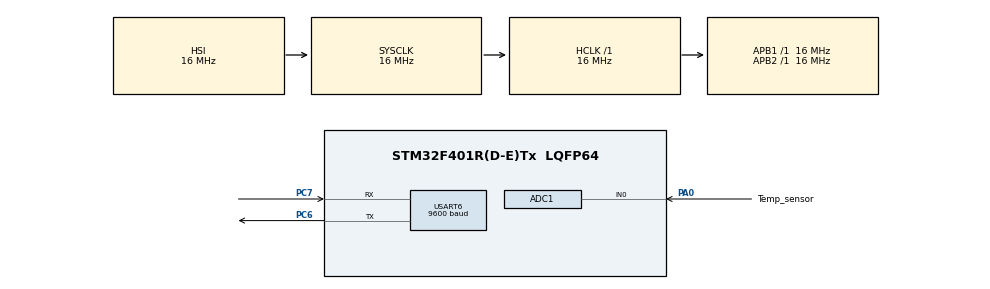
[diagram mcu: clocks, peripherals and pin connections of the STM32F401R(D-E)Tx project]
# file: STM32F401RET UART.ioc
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ADC1.Channel-2\#ChannelRegularConversion=ADC_CHANNEL_0
ADC1.NbrOfConversionFlag=1
ADC1.Rank-2\#ChannelRegularConversion=1
ADC1.Resolution=ADC_RESOLUTION_10B
ADC1.SamplingTime-2\#ChannelRegularConversion=ADC_SAMPLETIME_3CYCLES
ADC1.master=1
Mcu.Family=STM32F4
Mcu.Name=STM32F401R(D-E)Tx
Mcu.Package=LQFP64
NVIC.PriorityGroup=NVIC_PRIORITYGROUP_4
PA0-WKUP.GPIO_Label=Temp_sensor
PA0-WKUP.Signal=ADCx_IN0
PC6.Mode=Asynchronous
PC6.Signal=USART6_TX
PC7.Mode=Asynchronous
PC7.Signal=USART6_RX
ProjectManager.HeapSize=0x200
ProjectManager.StackSize=0x400
ProjectManager.TargetToolchain=MDK-ARM V5.27
RCC.AHBFreq_Value=16000000
RCC.APB1Freq_Value=16000000
RCC.APB2Freq_Value=16000000
RCC.CortexFreq_Value=16000000
RCC.HSE_VALUE=25000000
RCC.HSI_VALUE=16000000
RCC.LSE_VALUE=32768
RCC.SYSCLKFreq_VALUE=16000000
RCC.VCOOutputFreq_Value=192000000
SH.ADCx_IN0.0=ADC1_IN0,IN0
USART6.BaudRate=9600
USART6.VirtualMode=VM_ASYNC
board=custom

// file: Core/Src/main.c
/* USER CODE BEGIN Header */
/**
  ******************************************************************************
  * @file           : main.c
  * @brief          : Main program body
  ******************************************************************************
/*Info
*Developer: Harry Hoa Huynh
*Email: harry.hoa.huynh.01@gmail.com
*Date: 4/11/2021
*Version: 001
*Main goal: 	1. Collect temperature data using STM32F401RE
*							2. Send data to STM32F429ZI via UART using Polling
*							3. Display data on the LCD on the STM32F429ZI
*
*STM32F401RE Set up:
*1. Temperature MCP9700A: PA0	[ADC 10bits with 13 clock cycles]
*2. UART: TX = PC6 | RX = PC7 [Baud rate of 9600bs, Word length of 8b]
*
*STM32F429ZI Set up
*1. UART: TX = PC6 | RX = PC7 [Baud rate of 9600bs, Word length of 8b]
*2. Display the temperature via LCD
*		*	RS	PD1
*			EN	PD7
*			DB4	PD6
*			DB5	PD5
*			DB6	PD4
*			DB7	PD3
*
*		Component:
*		1. STM Nucleo STM32F429ZI
*		2. STM Nucleo STM32F401RE
*		3. Temperature MCP9700A
*		4. LCD HC16102

*/
/* USER CODE END Header */
#include "main.h"

/* USER CODE BEGIN Includes */
#include <string.h>

/* USER CODE END Includes */

ADC_HandleTypeDef hadc1;
UART_HandleTypeDef huart6;

/* USER CODE BEGIN PV */
uint32_t ADC_value;
float temperature_value;
char TX_buffer[4]={0};
char RX_buffer[4]={0};
/* USER CODE END PV */

void SystemClock_Config(void);
static void MX_GPIO_Init(void);
static void MX_USART6_UART_Init(void);
static void MX_ADC1_Init(void);

int main(void)
{

  /* MCU Configuration--------------------------------------------------------*/

  /* Reset of all peripherals, Initializes the Flash interface and the Systick. */
  HAL_Init();

  /* Configure the system clock */
  SystemClock_Config();

  /* Initialize all configured peripherals */
  MX_GPIO_Init();
  MX_USART6_UART_Init();
  MX_ADC1_Init();

  /* Infinite loop */
  while (1)
  {

    /* USER CODE BEGIN 3 */

		//Collect Temperature Data
		HAL_ADC_Start(&hadc1);
		HAL_ADC_PollForConversion(&hadc1, HAL_MAX_DELAY);
		ADC_value = HAL_ADC_GetValue(&hadc1);
		temperature_value = ((ADC_value*3.3)/1024 -0.5)/0.01;		//Input of 3.3V to the Sensor | Sensor Output Calibrated with  0.5V offset (MCP9700/9700A datasheet)

		//Transfer Data via UART
		sprintf(TX_buffer, "%d", ADC_value);	//Return a formatted string
		HAL_UART_Transmit(&huart6, (uint8_t*)TX_buffer, 5, 100);
		HAL_Delay(100);
  }
  /* USER CODE END 3 */
}

void SystemClock_Config(void)
{
  RCC_OscInitTypeDef RCC_OscInitStruct = {0};
  RCC_ClkInitTypeDef RCC_ClkInitStruct = {0};

  /** Configure the main internal regulator output voltage
  */
  __HAL_RCC_PWR_CLK_ENABLE();
  __HAL_PWR_VOLTAGESCALING_CONFIG(PWR_REGULATOR_VOLTAGE_SCALE2);
  /** Initializes the RCC Oscillators according to the specified parameters
  * in the RCC_OscInitTypeDef structure.
  */
  RCC_OscInitStruct.OscillatorType = RCC_OSCILLATORTYPE_HSI;
  RCC_OscInitStruct.HSIState = RCC_HSI_ON;
  RCC_OscInitStruct.HSICalibrationValue = RCC_HSICALIBRATION_DEFAULT;
  RCC_OscInitStruct.PLL.PLLState = RCC_PLL_NONE;
  if (HAL_RCC_OscConfig(&RCC_OscInitStruct) != HAL_OK)
  {
    Error_Handler();
  }
  /** Initializes the CPU, AHB and APB buses clocks
  */
  RCC_ClkInitStruct.ClockType = RCC_CLOCKTYPE_HCLK|RCC_CLOCKTYPE_SYSCLK
                              |RCC_CLOCKTYPE_PCLK1|RCC_CLOCKTYPE_PCLK2;
  RCC_ClkInitStruct.SYSCLKSource = RCC_SYSCLKSOURCE_HSI;
  RCC_ClkInitStruct.AHBCLKDivider = RCC_SYSCLK_DIV1;
  RCC_ClkInitStruct.APB1CLKDivider = RCC_HCLK_DIV1;
  RCC_ClkInitStruct.APB2CLKDivider = RCC_HCLK_DIV1;

  if (HAL_RCC_ClockConfig(&RCC_ClkInitStruct, FLASH_LATENCY_0) != HAL_OK)
  {
    Error_Handler();
  }
}

static void MX_ADC1_Init(void)
{

  ADC_ChannelConfTypeDef sConfig = {0};

  /** Configure the global features of the ADC (Clock, Resolution, Data Alignment and number of conversion)
  */
  hadc1.Instance = ADC1;
  hadc1.Init.ClockPrescaler = ADC_CLOCK_SYNC_PCLK_DIV2;
  hadc1.Init.Resolution = ADC_RESOLUTION_10B;
  hadc1.Init.ScanConvMode = DISABLE;
  hadc1.Init.ContinuousConvMode = DISABLE;
  hadc1.Init.DiscontinuousConvMode = DISABLE;
  hadc1.Init.ExternalTrigConvEdge = ADC_EXTERNALTRIGCONVEDGE_NONE;
  hadc1.Init.ExternalTrigConv = ADC_SOFTWARE_START;
  hadc1.Init.DataAlign = ADC_DATAALIGN_RIGHT;
  hadc1.Init.NbrOfConversion = 1;
  hadc1.Init.DMAContinuousRequests = DISABLE;
  hadc1.Init.EOCSelection = ADC_EOC_SINGLE_CONV;
  if (HAL_ADC_Init(&hadc1) != HAL_OK)
  {
    Error_Handler();
  }
  /** Configure for the selected ADC regular channel its corresponding rank in the sequencer and its sample time.
  */
  sConfig.Channel = ADC_CHANNEL_0;
  sConfig.Rank = 1;
  sConfig.SamplingTime = ADC_SAMPLETIME_3CYCLES;
  if (HAL_ADC_ConfigChannel(&hadc1, &sConfig) != HAL_OK)
  {
    Error_Handler();
  }

}

static void MX_USART6_UART_Init(void)
{

  huart6.Instance = USART6;
  huart6.Init.BaudRate = 9600;
  huart6.Init.WordLength = UART_WORDLENGTH_8B;
  huart6.Init.StopBits = UART_STOPBITS_1;
  huart6.Init.Parity = UART_PARITY_NONE;
  huart6.Init.Mode = UART_MODE_TX_RX;
  huart6.Init.HwFlowCtl = UART_HWCONTROL_NONE;
  huart6.Init.OverSampling = UART_OVERSAMPLING_16;
  if (HAL_UART_Init(&huart6) != HAL_OK)
  {
    Error_Handler();
  }

}

static void MX_GPIO_Init(void)
{

  /* GPIO Ports Clock Enable */
  __HAL_RCC_GPIOA_CLK_ENABLE();
  __HAL_RCC_GPIOC_CLK_ENABLE();

}

/* USER CODE BEGIN 4 */
/*******************************
 * UART Communication()
 * Inputs: NONE
 * Outputs: NONE
 * Send UART
 *
 *******************************
 */

void UART_Transmit_HH(char *str){
	//HAL_UART_Transmit(&huart6, (uint8_t*)str, strlen(str), 100);
	HAL_UART_Transmit(&huart6, (uint8_t*)str, 5, 100);
}
/* USER CODE END 4 */

void Error_Handler(void)
{
  __disable_irq();
  while (1)
  {
  }
}

/************************ (C) COPYRIGHT STMicroelectronics *****END OF FILE****/
